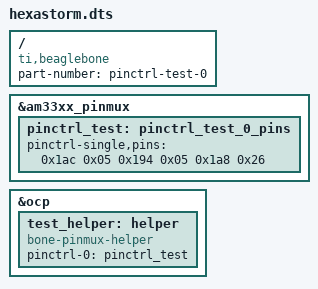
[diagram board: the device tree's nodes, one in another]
/*
 * Copyright (C) 2012 Texas Instruments Incorporated - http://www.ti.com/
 *
 * This program is free software; you can redistribute it and/or modify
 * it under the terms of the GNU General Public License version 2 as
 * published by the Free Software Foundation.
 */
/dts-v1/;
/plugin/;

/ {
	compatible = "ti,beaglebone", "ti,beaglebone-black";

	/* identification */
	part-number = "pinctrl-test-0";

	fragment@0 {
		target = <&am33xx_pinmux>;
		__overlay__ {
			pinctrl_test: pinctrl_test_0_pins {
				pinctrl-single,pins = <
					0x1ac 0x05  /* P9.25 Polygon PWM */
                    0x194 0x05	/* P9.29 Laserdiode  */
				    0x1a8 0x26  /* P9.41 Photodiode  */
				>;
			};
		};
	};

	fragment@1 {
		target = <&ocp>;
		__overlay__ {
			test_helper: helper {
				compatible = "bone-pinmux-helper";
				pinctrl-names = "default";
				pinctrl-0 = <&pinctrl_test>;
				status = "okay";
			};
		};
	};
};
